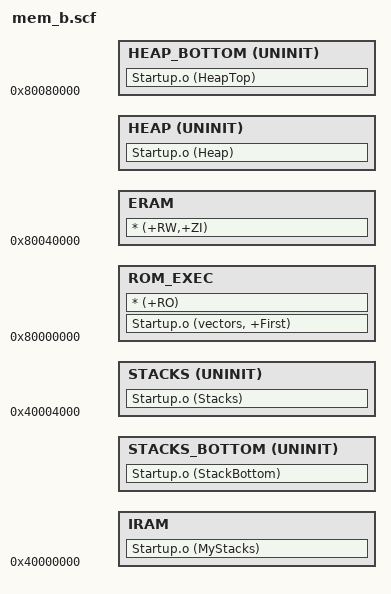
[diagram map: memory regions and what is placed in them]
;/****************************************Copyright (c)**************************************************
;**                               Guangzou ZLG-MCU Development Co.,LTD.
;**                                      graduate school
;**                                 http://www.zlgmcu.com
;**
;**--------------File Info-------------------------------------------------------------------------------
;** File Name: men_b.scf
;** Last modified Date:  2004-09-17
;** Last Version: 1.0
;** Descriptions: Scatter File
;**
;**------------------------------------------------------------------------------------------------------
;** Created By: Chenmingji
;** Created date:   2004-09-17
;** Version: 1.0
;** Descriptions: First version
;**
;**------------------------------------------------------------------------------------------------------
;** Modified by:
;** Modified date:
;** Version:
;** Descriptions:
;**
;********************************************************************************************************/

ROM_LOAD 0x80000000
{
    ROM_EXEC 0x80000000
    {
        Startup.o (vectors, +First)
        * (+RO)
    }


    IRAM 0x40000000
    {
        Startup.o (MyStacks)
    }

    STACKS_BOTTOM +0 UNINIT
    {
        Startup.o (StackBottom)
    }

    STACKS 0x40004000 UNINIT
    {
        Startup.o (Stacks)
    }

    ERAM 0x80040000
    {
        * (+RW,+ZI)
    }

    HEAP +0 UNINIT
    {
        Startup.o (Heap)
    }

    HEAP_BOTTOM 0x80080000 UNINIT
    {
        Startup.o (HeapTop)
    }

}

